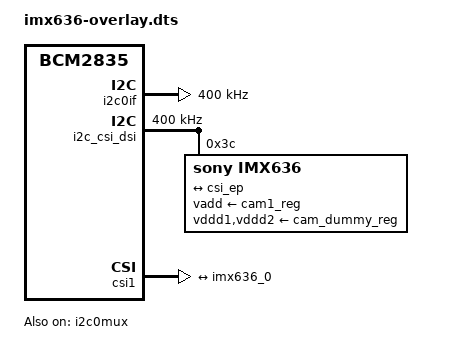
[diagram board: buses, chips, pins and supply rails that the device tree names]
// SPDX-License-Identifier: GPL-2.0-only
// Definitions for GenX320 camera module on VC I2C bus
/dts-v1/;
/plugin/;

// #include <dt-bindings/gpio/gpio.h>

/{
	compatible = "brcm,bcm2835";

	fragment@0 {
		target = <&i2c0if>;
		__overlay__ {
			status = "okay";
			clock-frequency = <400000>;
		};
	};

	clk_frag: fragment@1 {
		target = <&cam1_clk>;
		__overlay__ {
			status = "okay";
			clock-frequency = <20000000>;
		};
	};

	fragment@2 {
		target = <&i2c0mux>;
		__overlay__ {
			status = "okay";
		};
	};

	reg_frag: fragment@5 {
		target = <&cam1_reg>;
		cam_reg: __overlay__ {
			startup-delay-us = <500000>;
		};
	};

	reg_alwayson_frag: fragment@99 {
		target = <&cam1_reg>;
		__dormant__ {
			regulator-always-on;
		};
	};

	i2c_frag: fragment@100 {
		target = <&i2c_csi_dsi>;
		__overlay__ {
			#address-cells = <1>;
			#size-cells = <0>;
			status = "okay";
			clock-frequency = <400000>;
			imx636: imx636@3c {
				compatible = "sony,imx636";
				reg = <0x3c>;
				status = "okay";

				clocks = <&cam1_clk>;
 				clock-names = "inclk";

				vadd-supply = <&cam1_reg>;
				vddd1-supply = <&cam_dummy_reg>;
				vddd2-supply = <&cam_dummy_reg>;

				rotation = <180>;
				orientation = <2>;

				rstn-delay-ms = <285>;

				port {
					imx636_0: endpoint {
						remote-endpoint = <&csi_ep>;
						clock-lanes = <0>;
						data-lanes = <1 2>;
						clock-noncontinuous;
						link-frequencies = /bits/ 64 <750000000>;
					};
				};
			};
		};
	};

	csi_frag: fragment@101 {
		target = <&csi1>;
		csi: __overlay__ {
			status = "okay";
			brcm,media-controller;

			port {
				csi_ep: endpoint {
					remote-endpoint = <&imx636_0>;
					clock-lanes = <0>;
					data-lanes = <1 2>;
					clock-noncontinuous;
				};
			};
		};
	};

	__overrides__ {
		rotation = <&imx636>,"rotation:0";
		orientation = <&imx636>,"orientation:0";
		media-controller = <&csi>,"brcm,media-controller?";
		cam0 = <&i2c_frag>, "target:0=",<&i2c_csi_dsi0>,
		 		<&csi_frag>, "target:0=",<&csi0>,
				<&clk_frag>, "target:0=",<&cam0_clk>,
				<&reg_frag>, "target:0=",<&cam0_reg>,
				<&reg_alwayson_frag>, "target:0=",<&cam0_reg>,
				<&imx636>, "clocks:0=",<&cam0_clk>,
				<&imx636>, "vadd-supply:0=",<&cam0_reg>;
		always-on = <0>, "+99";
	};
};
